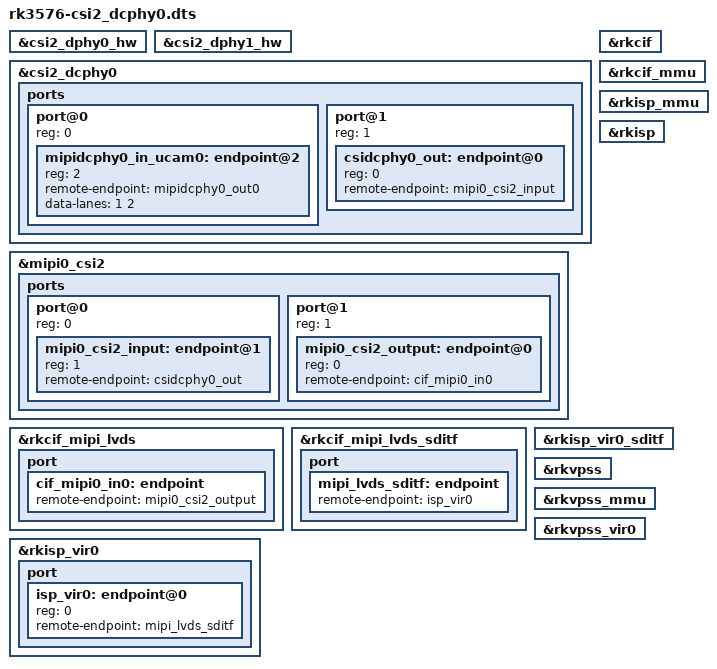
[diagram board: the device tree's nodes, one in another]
&csi2_dphy0_hw {
	status = "okay";
};

&csi2_dphy1_hw {
	status = "okay";
};

&csi2_dcphy0 {
	status = "okay";

	ports {
		#address-cells = <1>;
		#size-cells = <0>;

		port@0 {
			reg = <0>;
			#address-cells = <1>;
			#size-cells = <0>;

			mipidcphy0_in_ucam0: endpoint@2 {
				reg = <2>;
				remote-endpoint = <&mipidcphy0_out0>;
				data-lanes = <1 2>;
			};
		};

		port@1 {
			reg = <1>;
			#address-cells = <1>;
			#size-cells = <0>;

			csidcphy0_out: endpoint@0 {
				reg = <0>;
				remote-endpoint = <&mipi0_csi2_input>;
			};
		};
	};
};

&mipi0_csi2 {
	status = "okay";

	ports {
		#address-cells = <1>;
		#size-cells = <0>;

		port@0 {
			reg = <0>;
			#address-cells = <1>;
			#size-cells = <0>;

			mipi0_csi2_input: endpoint@1 {
				reg = <1>;
				remote-endpoint = <&csidcphy0_out>;
			};
		};

		port@1 {
			reg = <1>;
			#address-cells = <1>;
			#size-cells = <0>;

			mipi0_csi2_output: endpoint@0 {
				reg = <0>;
				remote-endpoint = <&cif_mipi0_in0>;
			};
		};
	};
};

&rkcif {
	status = "okay";
};

&rkcif_mmu {
	status = "okay";
};

&rkcif_mipi_lvds {
	status = "okay";

	port {
		cif_mipi0_in0: endpoint {
			remote-endpoint = <&mipi0_csi2_output>;
		};
	};
};

&rkcif_mipi_lvds_sditf {
	status = "okay";

	port {
		mipi_lvds_sditf: endpoint {
			remote-endpoint = <&isp_vir0>;
		};
	};
};

&rkisp_mmu {
	status = "okay";
};

&rkisp {
	status = "okay";
};

&rkisp_vir0 {
	status = "okay";

	port {
		#address-cells = <1>;
		#size-cells = <0>;

		isp_vir0: endpoint@0 {
			reg = <0>;
			remote-endpoint = <&mipi_lvds_sditf>;
		};
	};
};

&rkisp_vir0_sditf {
	status = "okay";
};

&rkvpss {
	status = "okay";
};

&rkvpss_mmu {
	status = "okay";
};

&rkvpss_vir0 {
	status = "okay";
};
